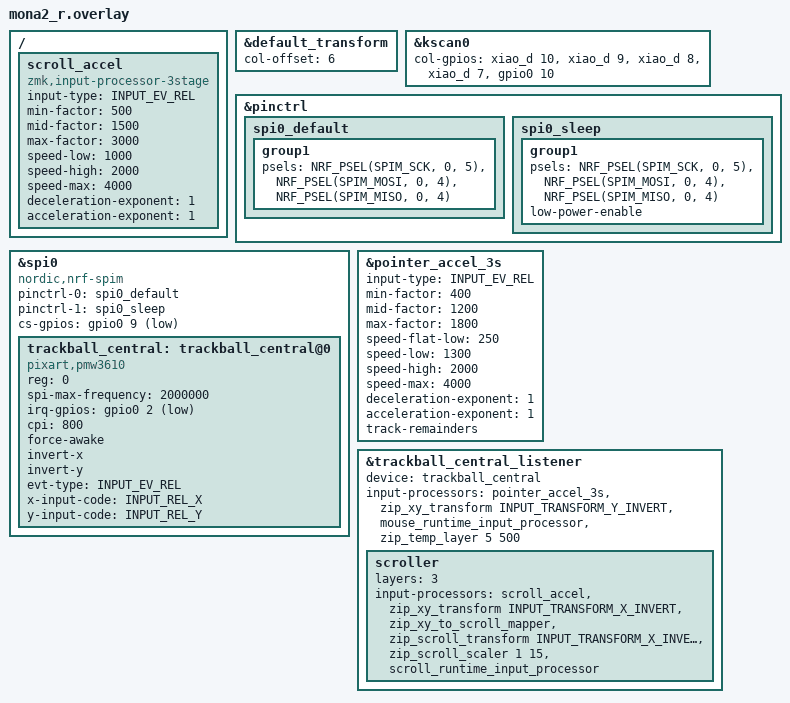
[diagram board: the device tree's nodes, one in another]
#include "mona2.dtsi"
#include <input/processors.dtsi>
#include <zephyr/dt-bindings/input/input-event-codes.h>
#include <behaviors/input_processor_3stage.dtsi>


&default_transform {
    col-offset = <6>;
};

&kscan0 {
        col-gpios
            = <&xiao_d 10 GPIO_ACTIVE_HIGH>
            , <&xiao_d 9 GPIO_ACTIVE_HIGH>
            , <&xiao_d 8 GPIO_ACTIVE_HIGH>
            , <&xiao_d 7 GPIO_ACTIVE_HIGH>
            , <&gpio0 10 GPIO_ACTIVE_HIGH>
            ;
};


&pinctrl {
    spi0_default: spi0_default {    //通常時(SPI通信中)のピン構成
        group1 {
            psels = <NRF_PSEL(SPIM_SCK, 0, 5)>, //P0.05を指定(SCLK)
                <NRF_PSEL(SPIM_MOSI, 0, 4)>,    //P0.04を指定(SDIOだからMOSI,MISO両方の役割を担う)
                <NRF_PSEL(SPIM_MISO, 0, 4)>;
        };
    };

    spi0_sleep: spi0_sleep {    //スリープ時のピン構成(省電力)
        group1 {
            psels = <NRF_PSEL(SPIM_SCK, 0, 5)>,
                <NRF_PSEL(SPIM_MOSI, 0, 4)>,
                <NRF_PSEL(SPIM_MISO, 0, 4)>;
            low-power-enable;
        };
    };
};


&spi0 {
    status = "okay";
    compatible = "nordic,nrf-spim"; //マイコンがnRFシリーズ
    pinctrl-0 = <&spi0_default>;
    pinctrl-1 = <&spi0_sleep>;
    pinctrl-names = "default", "sleep";
    cs-gpios = <&gpio0 9 GPIO_ACTIVE_LOW>;  //P0.09を指定(CS)

    trackball_central: trackball_central@0 {
        status = "okay";
        compatible = "pixart,pmw3610";  //トラボセンサ用のドライバとバインド
        reg = <0>;
        spi-max-frequency = <2000000>;
        irq-gpios = <&gpio0 2 (GPIO_ACTIVE_LOW | GPIO_PULL_UP)>; //P0.02を指定(MOTION)
        cpi = <800>;
        force-awake;
        //swap-xy;
        invert-x; //COROPIT版ではコメントアウトを外す
        invert-y; //COROPIT版ではコメントアウトを外す
        evt-type = <INPUT_EV_REL>;
        x-input-code = <INPUT_REL_X>;
        y-input-code = <INPUT_REL_Y>;
    };
};

// 5-zone pointer acceleration config
// Zone A (0-250 cps):      flat at 0.4x (precision low flat)
// Zone B (250-1300 cps):   ramp 0.4x → 1.2x
// Zone C (1300-2000 cps):  flat at 1.2x (normal)
// Zone D (2000-4000 cps):  ramp 1.2x → 1.8x (fast travel)
// Zone E (>4000 cps):      flat at 1.8x
&pointer_accel_3s {
    status = "okay";
    input-type = <INPUT_EV_REL>;
    min-factor = <400>;           // 0.4x low flat zone
    mid-factor = <1200>;          // 1.2x mid flat zone
    max-factor = <1800>;          // 1.8x top speed
    speed-flat-low = <250>;       // end of low flat zone
    speed-low = <1300>;           // ramp → mid flat boundary
    speed-high = <2000>;          // mid flat → accel boundary
    speed-max = <4000>;           // max-factor reached here
    deceleration-exponent = <1>;  // linear ramp (low → mid)
    acceleration-exponent = <1>;  // linear ramp (mid → max)
    track-remainders;
};

// Scroll acceleration config (gentle linear curve, 2-stage mode)
/ {
    scroll_accel: scroll_accel {
        compatible = "zmk,input-processor-3stage";
        status = "okay";
        #input-processor-cells = <0>;
        input-type = <INPUT_EV_REL>;
        min-factor = <500>;           // 0.5x at slow speeds
        mid-factor = <1500>;          // 1.5x in flat zone
        max-factor = <3000>;          // 3.0x at fast speeds
        speed-low = <1000>;           // decel -> flat boundary
        speed-high = <2000>;          // flat -> accel boundary
        speed-max = <4000>;           // max accel reached here
        deceleration-exponent = <1>;
        acceleration-exponent = <1>;  // linear curve (gentle)
    };
};

// Overrides for the input listener node
&trackball_central_listener {
    status = "okay";
    device = <&trackball_central>;
    input-processors = <&pointer_accel_3s>, <&zip_xy_transform INPUT_TRANSFORM_Y_INVERT>, <&mouse_runtime_input_processor>, <&zip_temp_layer 5 500>;

    scroller {
        layers = <3>;
        input-processors =
            <&scroll_accel>,                                    //スクロール加速度（緩やか）
            // <&zip_xy_transform INPUT_TRANSFORM_XY_SWAP>,     //X軸とY軸の入れ替え
            <&zip_xy_transform INPUT_TRANSFORM_X_INVERT>,       //X軸反転
            <&zip_xy_to_scroll_mapper>,                         //スクロールモードに変更
            <&zip_scroll_transform INPUT_TRANSFORM_X_INVERT>,   //スクロールのX軸反転
            <&zip_scroll_scaler 1 15>,                           //スクロール量を1/5倍
            <&scroll_runtime_input_processor>;                  //DYA Studioからスクロール速度変更可能
    };

};
